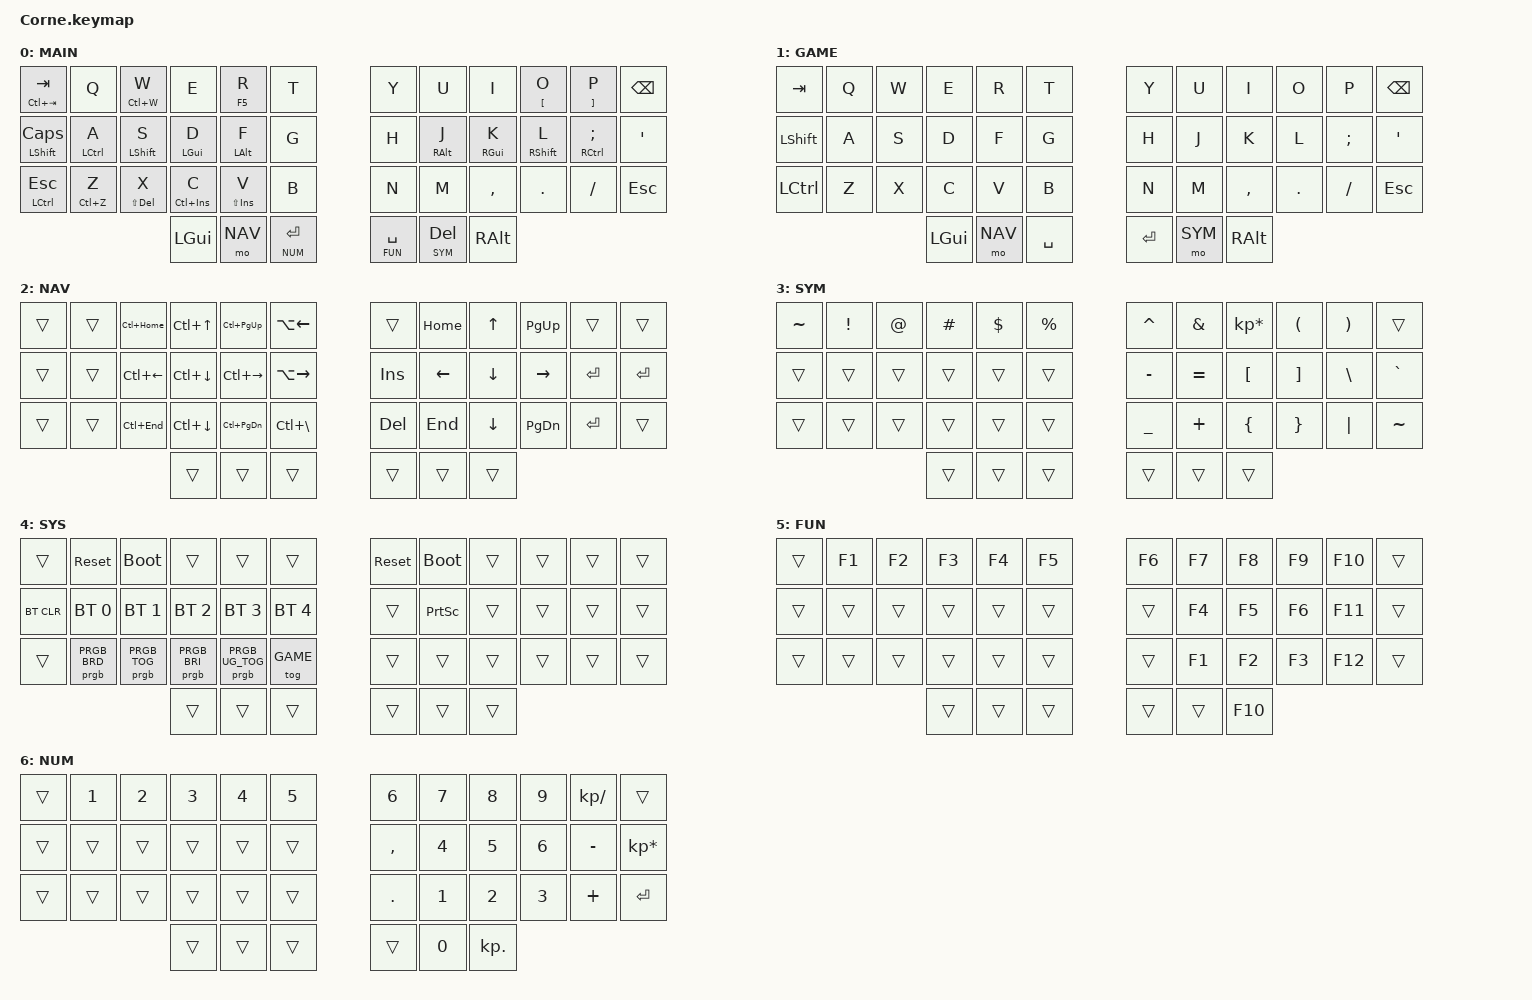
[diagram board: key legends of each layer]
/*
 * Copyright (c) 2020 The ZMK Contributors
 *
 * SPDX-License-Identifier: MIT
 */

#include <behaviors.dtsi>
#include <dt-bindings/zmk/bt.h>
#include <dt-bindings/zmk/ext_power.h>
#include <dt-bindings/zmk/keys.h>
#include <dt-bindings/zmk/corne_positions.h>
#include <dt-bindings/zmk/perkey_rgb.h>

// Layer numbers are the order of the children of the keymap node below.
// GAME sits directly above MAIN so that, while it is toggled on, the layers
// above it can still shadow it: a fully opaque layer at the top would hide
// NAV, SYM and SYS, leaving no way back out.
#define MAIN 0
#define GAME 1
#define NAV  2
#define SYM  3
#define SYS  4
#define FUN  5
#define NUM  6

&mt {
    tapping-term-ms = <300>;
    flavor = "tap-preferred";
    require-prior-idle-ms = <150>;
};

/ {
    // Reusable position sets. Declared once, coloured where they are used.

    // The right hand's 3x3 block. It is the navigation pad on NAV, the numpad
    // on NUM and F7-F9/F4-F6/F1-F3 on FUN, so all three layers point at it.
    prgb_pad_r: prgb_pad_r {
        compatible = "zmk,perkey-rgb-zone";
        #zone-cells = <3>;
        positions = <POS_T8 POS_T9 POS_T10     // home  up    pgup  /  7 8 9
                     POS_H8 POS_H9 POS_H10     // left  down  right /  4 5 6
                     POS_B8 POS_B9 POS_B10>;   // end   down  pgdn  /  1 2 3
    };

    // The left hand's mirror of it, the same navigation keys with ctrl.
    prgb_pad_l: prgb_pad_l {
        compatible = "zmk,perkey-rgb-zone";
        #zone-cells = <3>;
        positions = <POS_T3 POS_T4 POS_T5      // ctrl home / up   / pgup
                     POS_H3 POS_H4 POS_H5      // ctrl left / down / right
                     POS_B3 POS_B4 POS_B5>;    // ctrl end  / down / pgdn
    };

    prgb_num_zero: prgb_num_zero {
        compatible = "zmk,perkey-rgb-zone";
        #zone-cells = <3>;
        positions = <POS_TH5>;                 // 0
    };

    // F10, F11, F12 down the outer column, completing F1-F12.
    prgb_fn_col: prgb_fn_col {
        compatible = "zmk,perkey-rgb-zone";
        #zone-cells = <3>;
        positions = <POS_T11 POS_H11 POS_B11>;
    };

    perkey_rgb {
        compatible = "zmk,perkey-rgb";

        // <hue 0-359  saturation 0-100  value 0-100>
        default-color   = <200 100  70>;
        unbound-value   = <6>;             // no function here: layer colour, darkened
        modifier-color  = <  0   0 100>;   // white

        // Only used on a layer with no entry below; otherwise the six
        // underglow LEDs follow the active layer's colour.
        underglow-color = <200 100  50>;

        // Press feedback, for verifying the LED map. Leaving it out means an
        // ordinary typing session emits no LED updates at all.
        // pressed-color = <0 0 100>;

        // A key that reaches another layer is painted in that layer's colour,
        // so the thumbs advertise where they go.
        main { layer = <MAIN>; color = <200 100  70>; };

        nav {
            layer = <NAV>;
            color = <120 100  70>;
            zones = <&prgb_pad_r 200 100 100>,   // navigation
                    <&prgb_pad_l 300 100 100>;   // same, with ctrl
        };

        sym { layer = <SYM>; color = <20 100 70>; };
        sys { layer = <SYS>; color = < 0 100 70>; };

        fun {
            layer = <FUN>;
            color = <285 100  70>;
            zones = <&prgb_pad_r  200 100 100>,  // F7-F9 / F4-F6 / F1-F3
                    <&prgb_fn_col 180 100 100>;  // F10-F12
        };

        num {
            layer = <NUM>;
            color = < 55 100  70>;
            zones = <&prgb_pad_r     200 100 100>,
                    <&prgb_num_zero  200 100 100>;
        };

        game { layer = <GAME>; color = < 90 100  70>; };
    };


    conditional_layers {
        compatible = "zmk,conditional-layers";

        sys_layer {
            if-layers = <SYM NAV>;
            then-layer = <SYS>;
        };
    };

    behaviors {
        prgb: prgb {
            compatible = "zmk,behavior-perkey-rgb";
            #binding-cells = <2>;
            display-name = "Per-key RGB";
        };

        hm: homerow_mods {
            compatible = "zmk,behavior-hold-tap";
            #binding-cells = <2>;
            tapping-term-ms = <220>;
            quick-tap-ms = <150>;
            require-prior-idle-ms = <125>;
            flavor = "tap-preferred";
            bindings = <&kp>, <&kp>;
        };
    };

    keymap {
        compatible = "zmk,keymap";

        default_layer {
            // -----------------------------------------------------------------------------------------
            // |  TAB |  Q  |  W  |  E  |  R  |  T  |   |  Y  |  U   |  I  |  O  |  P  | BKSP |
            // | CTRL |  A  |  S  |  D  |  F  |  G  |   |  H  |  J   |  K  |  L  |  ;  |  '   |
            // | SHFT |  Z  |  X  |  C  |  V  |  B  |   |  N  |  M   |  ,  |  .  |  /  | ESC  |
            //                    | GUI | LWR | ENT |   | SPC | RSE  | ALT |

            bindings = <
&mt LC(TAB) TAB &kp Q        &mt LC(W) W       &kp E                &mt F5 R            &kp T        &kp Y          &kp U           &kp I       &mt LBKT O   &mt RBKT P           &kp BSPC
&hm LSHFT CAPS  &hm LCTRL A  &hm LSHFT S       &hm LGUI D           &hm LALT F          &kp G        &kp H          &hm RALT J      &hm RGUI K  &hm RSHFT L  &hm RCTRL SEMI  &kp SQT
&hm LCTRL ESC   &mt LC(Z) Z  &mt LS(DELETE) X  &mt LC(INSERT) C     &mt LS(INSERT)  V   &kp B        &kp N          &kp M           &kp COMMA   &kp DOT      &kp FSLH        &kp ESC
                                               &kp LGUI             &mo NAV             &lt NUM RET  &lt FUN SPACE  &lt SYM DELETE  &kp RALT
            >;

            display-name = "MAIN";
        };

        game_layer {
            // Nothing here may be a hold-tap: every key reports the instant it
            // is pressed, so a held WASD or shift can never resolve as a tap.
            // Space sits on the left thumb, enter on the right.
            bindings = <
&kp TAB    &kp Q  &kp W  &kp E      &kp R       &kp T      &kp Y      &kp U    &kp I      &kp O    &kp P     &kp BSPC
&kp LSHFT  &kp A  &kp S  &kp D      &kp F       &kp G      &kp H      &kp J    &kp K      &kp L    &kp SEMI  &kp SQT
&kp LCTRL  &kp Z  &kp X  &kp C      &kp V       &kp B      &kp N      &kp M    &kp COMMA  &kp DOT  &kp FSLH  &kp ESC
                         &kp LGUI   &mo NAV     &kp SPACE  &kp RET    &mo SYM  &kp RALT
            >;

            display-name = "GAME";
        };

        nav_layer {
            bindings = <
&trans   &trans        &kp LC(HOME)  &kp LC(UP)          &kp LC(PAGE_UP)     &kp LA(LEFT)  &trans       &kp HOME  &kp UP          &kp PAGE_UP    &trans         &trans
&trans   &trans        &kp LC(LEFT)  &kp LC(DOWN)        &kp LC(RIGHT)       &kp LA(RIGHT) &kp INSERT   &kp LEFT  &kp DOWN        &kp RIGHT      &kp RET        &kp RET
&trans   &trans        &kp LC(END)   &kp LC(DOWN)        &kp LC(PAGE_DOWN)   &kp LC(BSLH)  &kp DELETE   &kp END   &kp DOWN        &kp PAGE_DOWN  &kp RET        &trans
                                     &trans              &trans              &trans        &trans       &trans    &trans
            >;

            display-name = "NAV";
        };

        sym_layer {
            bindings = <
&kp TILDE &kp EXCL  &kp AT        &kp HASH  &kp DLLR       &kp PRCNT  &kp CARET  &kp AMPS   &kp KP_MULTIPLY  &kp LPAR  &kp RPAR  &trans
&trans    &trans    &trans        &trans    &trans         &trans     &kp MINUS  &kp EQUAL  &kp LBKT         &kp RBKT  &kp BSLH  &kp GRAVE
&trans    &trans    &trans        &trans    &trans         &trans     &kp UNDER  &kp PLUS   &kp LBRC         &kp RBRC  &kp PIPE  &kp TILDE
                                  &trans    &trans         &trans     &trans     &trans     &trans
            >;

            display-name = "SYM";
        };

        sys_layer {
            bindings = <
&trans      &sys_reset       &bootloader      &trans           &trans             &trans           &sys_reset  &bootloader      &trans  &trans  &trans  &trans
&bt BT_CLR  &bt BT_SEL 0     &bt BT_SEL 1     &bt BT_SEL 2     &bt BT_SEL 3       &bt BT_SEL 4     &trans      &kp PRINTSCREEN  &trans  &trans  &trans  &trans
&trans      &prgb PRGB_BRD   &prgb PRGB_TOG   &prgb PRGB_BRI   &prgb PRGB_UG_TOG  &tog GAME        &trans      &trans           &trans  &trans  &trans  &trans
                                              &trans           &trans             &trans           &trans      &trans           &trans
            >;

            display-name = "SYS";
        };

        fun_layer {
            bindings = <
&trans   &kp F1  &kp F2  &kp F3    &kp F4  &kp F5  &kp F6  &kp F7  &kp F8   &kp F9  &kp F10  &trans
&trans   &trans  &trans  &trans    &trans  &trans  &trans  &kp F4  &kp F5   &kp F6  &kp F11  &trans
&trans   &trans  &trans  &trans    &trans  &trans  &trans  &kp F1  &kp F2   &kp F3  &kp F12  &trans
                         &trans    &trans  &trans  &trans  &trans  &kp F10
            >;

            display-name = "FUN";
        };

        num_layer {
            bindings = <
&trans   &kp N1  &kp N2  &kp N3    &kp N4  &kp N5  &kp N6     &kp N7  &kp N8   &kp N9  &kp KP_DIVIDE  &trans
&trans   &trans  &trans  &trans    &trans  &trans  &kp COMMA  &kp N4  &kp N5   &kp N6  &kp MINUS      &kp KP_MULTIPLY
&trans   &trans  &trans  &trans    &trans  &trans  &kp DOT    &kp N1  &kp N2   &kp N3  &kp PLUS       &kp RET
                         &trans    &trans  &trans  &trans     &kp N0  &kp KP_DOT
            >;

            display-name = "NUM";
        };

    };
};
